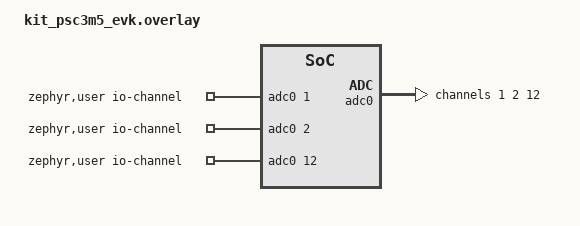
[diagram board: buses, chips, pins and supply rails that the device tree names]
/*
 * Copyright (c) 2025 Infineon Technologies AG,
 * or an affiliate of Infineon Technologies AG.
 *
 * SPDX-License-Identifier: Apache-2.0
 */

#include <zephyr/dt-bindings/adc/adc.h>

/ {
	zephyr,user {
		io-channels = <&adc0 1>, <&adc0 2>, <&adc0 12>;
	};
};

&adc0 {
	status = "okay";
	#address-cells = <1>; /* child channels */
	#size-cells = <0>;

	channel@1 {
		reg = <1>;
		zephyr,acquisition-time = <ADC_ACQ_TIME_DEFAULT>;
		zephyr,gain = "ADC_GAIN_1";
		zephyr,reference = "ADC_REF_INTERNAL";
		zephyr,resolution = <12>;
	};

	channel@2 {
		reg = <2>;
		zephyr,acquisition-time = <ADC_ACQ_TIME_DEFAULT>;
		zephyr,gain = "ADC_GAIN_1";
		zephyr,reference = "ADC_REF_INTERNAL";
		zephyr,resolution = <12>;
	};

	channel@12 {
		reg = <12>;
		zephyr,acquisition-time = <ADC_ACQ_TIME_DEFAULT>;
		zephyr,gain = "ADC_GAIN_1";
		zephyr,reference = "ADC_REF_INTERNAL";
		zephyr,resolution = <12>;
	};
};
